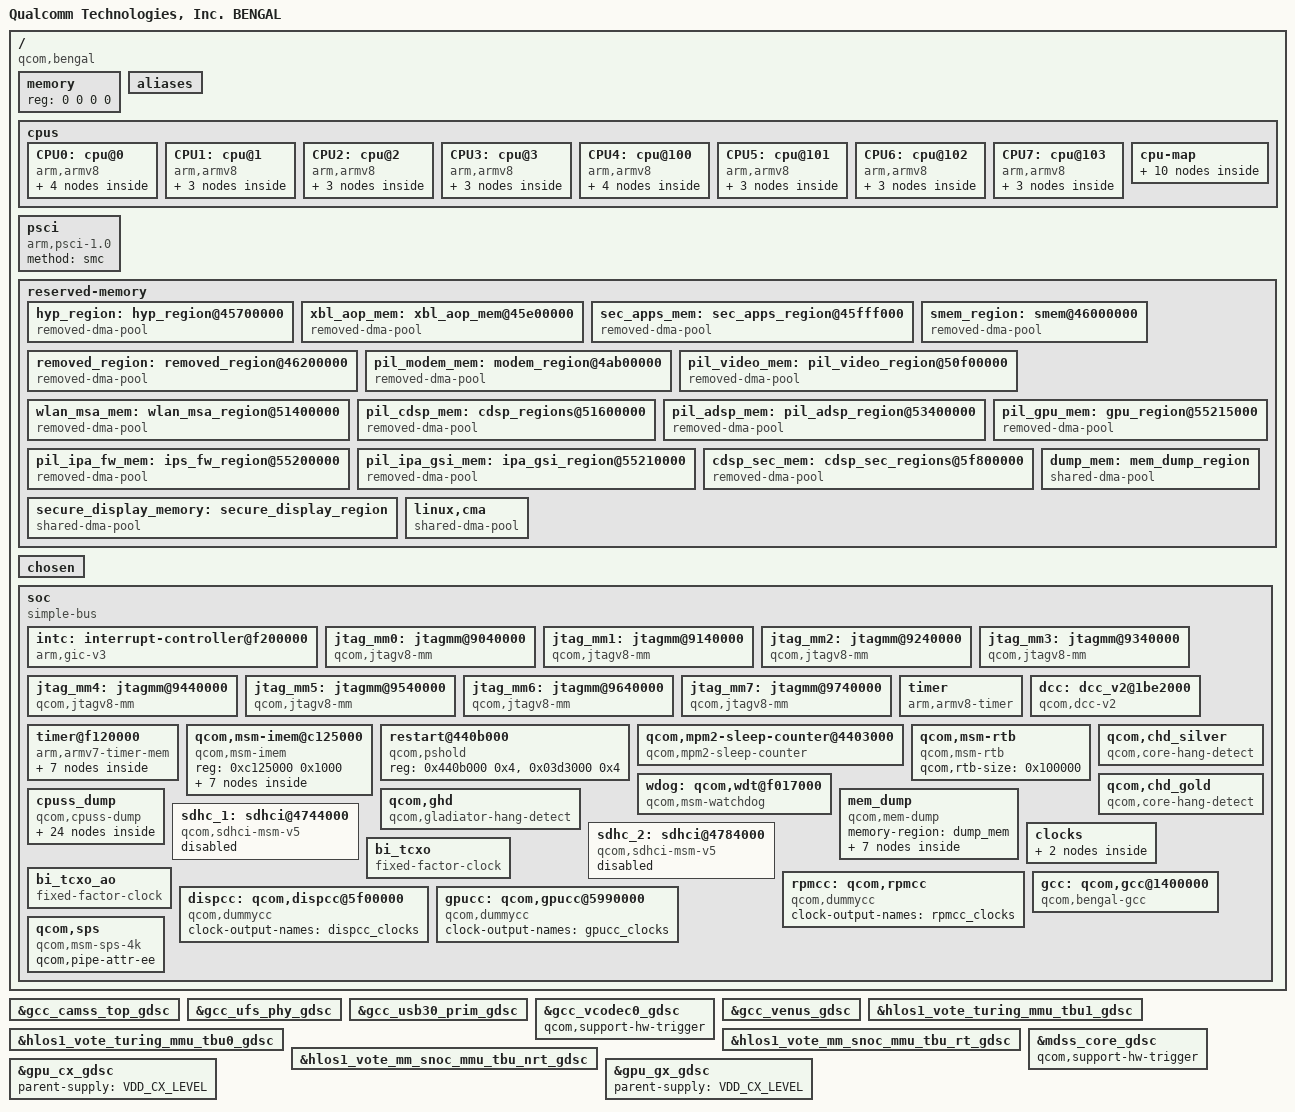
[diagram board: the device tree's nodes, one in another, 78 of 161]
#include <dt-bindings/interrupt-controller/arm-gic.h>
#include <dt-bindings/clock/qcom,rpmcc.h>
#include <dt-bindings/clock/qcom,dispcc-bengal.h>
#include <dt-bindings/clock/qcom,gcc-bengal.h>
#include <dt-bindings/clock/qcom,gpucc-bengal.h>

/ {
	model = "Qualcomm Technologies, Inc. BENGAL";
	compatible = "qcom,bengal";
	qcom,msm-id = <417 0x10000>;
	interrupt-parent = <&intc>;

	#address-cells = <2>;
	#size-cells = <2>;
	memory { device_type = "memory"; reg = <0 0 0 0>; };

	aliases {
		sdhc1 = &sdhc_1; /* SDC1 eMMC slot */
		sdhc2 = &sdhc_2; /* SDC2 SD Card slot */
	};

	cpus {
		#address-cells = <2>;
		#size-cells = <0>;

		CPU0: cpu@0 {
			device_type = "cpu";
			compatible = "arm,armv8";
			reg = <0x0 0x0>;
			capacity-dmips-mhz = <1024>;
			dynamic-power-coefficient = <100>;
			enable-method = "psci";
			d-cache-size = <0x8000>;
			i-cache-size = <0x8000>;
			next-level-cache = <&L2_0>;
			L2_0: l2-cache {
				compatible = "arm,arch-cache";
				cache-level = <2>;
			};

			L1_I_0: l1-icache {
				compatible = "arm,arch-cache";
				qcom,dump-size = <0x9040>;
			};

			L1_D_0: l1-dcache {
				compatible = "arm,arch-cache";
				qcom,dump-size = <0x9040>;
			};

			L1_TLB_0: l1-tlb {
				qcom,dump-size = <0x2800>;
			};
		};

		CPU1: cpu@1 {
			device_type = "cpu";
			compatible = "arm,armv8";
			reg = <0x0 0x1>;
			capacity-dmips-mhz = <1024>;
			dynamic-power-coefficient = <100>;
			enable-method = "psci";
			d-cache-size = <0x8000>;
			i-cache-size = <0x8000>;
			next-level-cache = <&L2_0>;

			L1_I_1: l1-icache {
				compatible = "arm,arch-cache";
				qcom,dump-size = <0x9040>;
			};

			L1_D_1: l1-dcache {
				compatible = "arm,arch-cache";
				qcom,dump-size = <0x9040>;
			};

			L1_TLB_1: l1-tlb {
				qcom,dump-size = <0x2800>;
			};
		};

		CPU2: cpu@2 {
			device_type = "cpu";
			compatible = "arm,armv8";
			reg = <0x0 0x2>;
			capacity-dmips-mhz = <1024>;
			dynamic-power-coefficient = <100>;
			enable-method = "psci";
			d-cache-size = <0x8000>;
			i-cache-size = <0x8000>;
			next-level-cache = <&L2_0>;

			L1_I_2: l1-icache {
				compatible = "arm,arch-cache";
				qcom,dump-size = <0x9040>;
			};

			L1_D_2: l1-dcache {
				compatible = "arm,arch-cache";
				qcom,dump-size = <0x9040>;
			};

			L1_TLB_2: l1-tlb {
				qcom,dump-size = <0x2800>;
			};
		};

		CPU3: cpu@3 {
			device_type = "cpu";
			compatible = "arm,armv8";
			reg = <0x0 0x3>;
			capacity-dmips-mhz = <1024>;
			dynamic-power-coefficient = <100>;
			enable-method = "psci";
			d-cache-size = <0x8000>;
			i-cache-size = <0x8000>;
			next-level-cache = <&L2_0>;

			L1_I_3: l1-icache {
				compatible = "arm,arch-cache";
				qcom,dump-size = <0x9040>;
			};

			L1_D_3: l1-dcache {
				compatible = "arm,arch-cache";
				qcom,dump-size = <0x9040>;
			};

			L1_TLB_3: l1-tlb {
				qcom,dump-size = <0x2800>;
			};
		};

		CPU4: cpu@100 {
			device_type = "cpu";
			compatible = "arm,armv8";
			reg = <0x0 0x100>;
			enable-method = "psci";
			capacity-dmips-mhz = <1638>;
			dynamic-power-coefficient = <282>;
			d-cache-size = <0x10000>;
			i-cache-size = <0x10000>;
			next-level-cache = <&L2_1>;
			L2_1: l2-cache {
				compatible = "arm,arch-cache";
				cache-level = <2>;
			};

			L1_I_100: l1-icache {
				compatible = "arm,arch-cache";
				qcom,dump-size = <0x12000>;
			};

			L1_D_100: l1-dcache {
				compatible = "arm,arch-cache";
				qcom,dump-size = <0x12000>;
			};

			L1_TLB_100: l1-tlb {
				qcom,dump-size = <0x4800>;
			};
		};

		CPU5: cpu@101 {
			device_type = "cpu";
			compatible = "arm,armv8";
			reg = <0x0 0x101>;
			capacity-dmips-mhz = <1638>;
			dynamic-power-coefficient = <282>;
			enable-method = "psci";
			d-cache-size = <0x10000>;
			i-cache-size = <0x10000>;
			next-level-cache = <&L2_1>;

			L1_I_101: l1-icache {
				compatible = "arm,arch-cache";
				qcom,dump-size = <0x12000>;
			};

			L1_D_101: l1-dcache {
				compatible = "arm,arch-cache";
				qcom,dump-size = <0x12000>;
			};

			L1_TLB_101: l1-tlb {
				qcom,dump-size = <0x4800>;
			};
		};

		CPU6: cpu@102 {
			device_type = "cpu";
			compatible = "arm,armv8";
			reg = <0x0 0x102>;
			capacity-dmips-mhz = <1638>;
			dynamic-power-coefficient = <282>;
			enable-method = "psci";
			d-cache-size = <0x10000>;
			i-cache-size = <0x10000>;
			next-level-cache = <&L2_1>;

			L1_I_102: l1-icache {
				compatible = "arm,arch-cache";
				qcom,dump-size = <0x12000>;
			};

			L1_D_102: l1-dcache {
				compatible = "arm,arch-cache";
				qcom,dump-size = <0x12000>;
			};

			L1_TLB_102: l1-tlb {
				qcom,dump-size = <0x4800>;
			};
		};

		CPU7: cpu@103 {
			device_type = "cpu";
			compatible = "arm,armv8";
			reg = <0x0 0x103>;
			capacity-dmips-mhz = <1638>;
			dynamic-power-coefficient = <282>;
			enable-method = "psci";
			d-cache-size = <0x10000>;
			i-cache-size = <0x10000>;
			next-level-cache = <&L2_1>;

			L1_I_103: l1-icache {
				compatible = "arm,arch-cache";
				qcom,dump-size = <0x12000>;
			};

			L1_D_103: l1-dcache {
				compatible = "arm,arch-cache";
				qcom,dump-size = <0x12000>;
			};

			L1_TLB_103: l1-tlb {
				qcom,dump-size = <0x4800>;
			};
		};

		cpu-map {
			cluster0 {
				core0 {
					cpu = <&CPU0>;
				};

				core1 {
					cpu = <&CPU1>;
				};

				core2 {
					cpu = <&CPU2>;
				};

				core3 {
					cpu = <&CPU3>;
				};
			};

			cluster1 {
				core0 {
					cpu = <&CPU4>;
				};

				core1 {
					cpu = <&CPU5>;
				};

				core2 {
					cpu = <&CPU6>;
				};

				core3 {
					cpu = <&CPU7>;
				};
			};
		};
	};

	psci {
		compatible = "arm,psci-1.0";
		method = "smc";
	};

	reserved-memory {
		#address-cells = <2>;
		#size-cells = <2>;
		ranges;

		hyp_region: hyp_region@45700000 {
			compatible = "removed-dma-pool";
			no-map;
			reg = <0x0 0x45700000 0x0 0x600000>;
		};

		xbl_aop_mem: xbl_aop_mem@45e00000 {
			compatible = "removed-dma-pool";
			no-map;
			reg = <0x0 0x45e00000 0x0 0x140000>;
		};

		sec_apps_mem: sec_apps_region@45fff000 {
			compatible = "removed-dma-pool";
			no-map;
			reg = <0x0 0x45fff000 0x0 0x1000>;
		};

		smem_region: smem@46000000 {
			compatible = "removed-dma-pool";
			no-map;
			reg = <0x0 0x46000000 0x0 0x200000>;
		};

		removed_region: removed_region@46200000 {
			compatible = "removed-dma-pool";
			no-map;
			reg = <0x0 0x46200000 0x0 0x3900000>;
		};

		pil_modem_mem: modem_region@4ab00000 {
			compatible = "removed-dma-pool";
			no-map;
			reg = <0x0 0x4ab00000 0x0 0x6400000>;
		};

		pil_video_mem: pil_video_region@50f00000 {
			compatible = "removed-dma-pool";
			no-map;
			reg = <0x0 0x50f00000 0x0 0x500000>;
		};

		wlan_msa_mem: wlan_msa_region@51400000 {
			compatible = "removed-dma-pool";
			no-map;
			reg = <0x0 0x51400000 0x0 0x200000>;
		};

		pil_cdsp_mem: cdsp_regions@51600000 {
			compatible = "removed-dma-pool";
			no-map;
			reg = <0x0 0x51600000 0x0 0x1e00000>;
		};

		pil_adsp_mem: pil_adsp_region@53400000 {
			compatible = "removed-dma-pool";
			no-map;
			reg = <0x0 0x53400000 0x0 0x1e00000>;
		};

		pil_ipa_fw_mem: ips_fw_region@55200000 {
			compatible = "removed-dma-pool";
			no-map;
			reg = <0x0 0x55200000 0x0 0x10000>;
		};

		pil_ipa_gsi_mem: ipa_gsi_region@55210000 {
			compatible = "removed-dma-pool";
			no-map;
			reg = <0x0 0x55210000 0x0 0x5000>;
		};

		pil_gpu_mem: gpu_region@55215000 {
			compatible = "removed-dma-pool";
			no-map;
			reg = <0x0 0x55215000 0x0 0x2000>;
		};

		cdsp_sec_mem: cdsp_sec_regions@5f800000 {
			compatible = "removed-dma-pool";
			no-map;
			reg = <0x0 0x5f800000 0x0 0x1e00000>;
		};

		secure_display_memory: secure_display_region {
			compatible = "shared-dma-pool";
			alloc-ranges = <0 0x00000000 0 0xffffffff>;
			reusable;
			alignment = <0 0x400000>;
			size = <0 0x5c00000>;
		};

		dump_mem: mem_dump_region {
			compatible = "shared-dma-pool";
			reusable;
			size = <0 0x400000>;
		};

		/* global autoconfigured region for contiguous allocations */
		linux,cma {
			compatible = "shared-dma-pool";
			alloc-ranges = <0x0 0x00000000 0x0 0xffffffff>;
			reusable;
			alignment = <0x0 0x400000>;
			size = <0x0 0x2000000>;
			linux,cma-default;
		};
	};

	chosen {
		bootargs = "rcupdate.rcu_expedited=1 rcu_nocbs=0-7";
	};

	soc: soc { };
};

&soc {
	#address-cells = <1>;
	#size-cells = <1>;
	ranges = <0 0 0 0xffffffff>;
	compatible = "simple-bus";

	intc: interrupt-controller@f200000 {
		compatible = "arm,gic-v3";
		#interrupt-cells = <3>;
		interrupt-controller;
		#redistributor-regions = <1>;
		redistributor-stride = <0x0 0x20000>;
		reg = <0xf200000 0x10000>,     /* GICD */
		      <0xf300000 0x100000>;    /* GICR * 8 */
		interrupts = <1 9 4>;
	};

	jtag_mm0: jtagmm@9040000 {
		compatible = "qcom,jtagv8-mm";
		reg = <0x9040000 0x1000>;
		reg-names = "etm-base";

		clocks = <&rpmcc RPM_SMD_QDSS_CLK>;
		clock-names = "core_clk";

		qcom,coresight-jtagmm-cpu = <&CPU0>;
	};

	jtag_mm1: jtagmm@9140000 {
		compatible = "qcom,jtagv8-mm";
		reg = <0x9140000 0x1000>;
		reg-names = "etm-base";

		clocks = <&rpmcc RPM_SMD_QDSS_CLK>;
		clock-names = "core_clk";

		qcom,coresight-jtagmm-cpu = <&CPU1>;
	};

	jtag_mm2: jtagmm@9240000 {
		compatible = "qcom,jtagv8-mm";
		reg = <0x9240000 0x1000>;
		reg-names = "etm-base";

		clocks = <&rpmcc RPM_SMD_QDSS_CLK>;
		clock-names = "core_clk";

		qcom,coresight-jtagmm-cpu = <&CPU2>;
	};

	jtag_mm3: jtagmm@9340000 {
		compatible = "qcom,jtagv8-mm";
		reg = <0x9340000 0x1000>;
		reg-names = "etm-base";

		clocks = <&rpmcc RPM_SMD_QDSS_CLK>;
		clock-names = "core_clk";

		qcom,coresight-jtagmm-cpu = <&CPU3>;
	};

	jtag_mm4: jtagmm@9440000 {
		compatible = "qcom,jtagv8-mm";
		reg = <0x9440000 0x1000>;
		reg-names = "etm-base";

		clocks = <&rpmcc RPM_SMD_QDSS_CLK>;
		clock-names = "core_clk";

		qcom,coresight-jtagmm-cpu = <&CPU4>;
	};

	jtag_mm5: jtagmm@9540000 {
		compatible = "qcom,jtagv8-mm";
		reg = <0x9540000 0x1000>;
		reg-names = "etm-base";

		clocks = <&rpmcc RPM_SMD_QDSS_CLK>;
		clock-names = "core_clk";

		qcom,coresight-jtagmm-cpu = <&CPU5>;
	};

	jtag_mm6: jtagmm@9640000 {
		compatible = "qcom,jtagv8-mm";
		reg = <0x9640000 0x1000>;
		reg-names = "etm-base";

		clocks = <&rpmcc RPM_SMD_QDSS_CLK>;
		clock-names = "core_clk";

		qcom,coresight-jtagmm-cpu = <&CPU6>;
	};

	jtag_mm7: jtagmm@9740000 {
		compatible = "qcom,jtagv8-mm";
		reg = <0x9740000 0x1000>;
		reg-names = "etm-base";

		clocks = <&rpmcc RPM_SMD_QDSS_CLK>;
		clock-names = "core_clk";

		qcom,coresight-jtagmm-cpu = <&CPU7>;
	};

	timer {
		compatible = "arm,armv8-timer";
		interrupts = <1 1 0xf08>,
			     <1 2 0xf08>,
			     <1 3 0xf08>,
			     <1 0 0xf08>;
		clock-frequency = <19200000>;
	};

	dcc: dcc_v2@1be2000 {
		compatible = "qcom,dcc-v2";
		reg = <0x1be2000 0x1000>,
			<0x1bee000 0x2000>;
		reg-names = "dcc-base", "dcc-ram-base";
		dcc-ram-offset = <0x2000>;
	};

	timer@f120000 {
		#address-cells = <1>;
		#size-cells = <1>;
		ranges;
		compatible = "arm,armv7-timer-mem";
		reg = <0xf120000 0x1000>;
		clock-frequency = <19200000>;

		frame@f121000 {
			frame-number = <0>;
			interrupts = <0 8 0x4>,
				     <0 7 0x4>;
			reg = <0xf121000 0x1000>,
			      <0xf122000 0x1000>;
		};

		frame@f123000 {
			frame-number = <1>;
			interrupts = <0 9 0x4>;
			reg = <0xf123000 0x1000>;
			status = "disabled";
		};

		frame@f124000 {
			frame-number = <2>;
			interrupts = <0 10 0x4>;
			reg = <0xf124000 0x1000>;
			status = "disabled";
		};

		frame@f125000 {
			frame-number = <3>;
			interrupts = <0 11 0x4>;
			reg = <0xf125000 0x1000>;
			status = "disabled";
		};

		frame@f126000 {
			frame-number = <4>;
			interrupts = <0 12 0x4>;
			reg = <0xf126000 0x1000>;
			status = "disabled";
		};

		frame@f127000 {
			frame-number = <5>;
			interrupts = <0 13 0x4>;
			reg = <0xf127000 0x1000>;
			status = "disabled";
		};

		frame@f128000 {
			frame-number = <6>;
			interrupts = <0 14 0x4>;
			reg = <0xf128000 0x1000>;
			status = "disabled";
		};
	};

	qcom,msm-imem@c125000 {
		compatible = "qcom,msm-imem";
		reg = <0xc125000 0x1000>;
		ranges = <0x0 0xc125000 0x1000>;
		#address-cells = <1>;
		#size-cells = <1>;

		mem_dump_table@10 {
			compatible = "qcom,msm-imem-mem_dump_table";
			reg = <0x10 0x8>;
		};

		restart_reason@65c {
			compatible = "qcom,msm-imem-restart_reason";
			reg = <0x65c 0x4>;
		};

		dload_type@1c {
			compatible = "qcom,msm-imem-dload-type";
			reg = <0x1c 0x4>;
		};

		boot_stats@6b0 {
			compatible = "qcom,msm-imem-boot_stats";
			reg = <0x6b0 0x20>;
		};

		kaslr_offset@6d0 {
			compatible = "qcom,msm-imem-kaslr_offset";
			reg = <0x6d0 0xc>;
		};

		pil@94c {
			compatible = "qcom,msm-imem-pil";
			reg = <0x94c 0xc8>;
		};

		diag_dload@c8 {
			compatible = "qcom,msm-imem-diag-dload";
			reg = <0xc8 0xc8>;
		};
	};

	restart@440b000 {
		compatible = "qcom,pshold";
		reg = <0x440b000 0x4>,
		      <0x03d3000 0x4>;
		reg-names = "pshold-base", "tcsr-boot-misc-detect";
	};

	qcom,mpm2-sleep-counter@4403000 {
		compatible = "qcom,mpm2-sleep-counter";
		reg = <0x4403000 0x1000>;
		clock-frequency = <32768>;
	};

	qcom,msm-rtb {
		compatible = "qcom,msm-rtb";
		qcom,rtb-size = <0x100000>;
	};

	wdog: qcom,wdt@f017000 {
		compatible = "qcom,msm-watchdog";
		reg = <0xf017000 0x1000>;
		reg-names = "wdt-base";
		interrupts = <0 3 0>, <0 4 0>;
		qcom,bark-time = <11000>;
		qcom,pet-time = <9360>;
		qcom,ipi-ping;
		qcom,wakeup-enable;
		qcom,scandump-sizes = <0x40000>;
	};

	qcom,chd_silver {
		compatible = "qcom,core-hang-detect";
		label = "silver";
		qcom,threshold-arr = <0x0f1880b0 0x0f1980b0
				      0x0f1a80b0 0x0f1b80b0>;
		qcom,config-arr = <0x0f1880b8 0x0f1980b8
				   0x0f1a80b8 0x0f1b80b8>;
	};

	qcom,chd_gold {
		compatible = "qcom,core-hang-detect";
		label = "gold";
		qcom,threshold-arr = <0x0f0880b0 0x0f0980b0
				      0x0f0a80b0 0x0f0b80b0>;
		qcom,config-arr = <0x0f0880b8 0x0f0980b8
				   0x0f0a80b8 0x0f0b80b8>;
	};

	qcom,ghd {
		compatible = "qcom,gladiator-hang-detect";
		qcom,threshold-arr = <0x0f1d141c 0x0f1d1420
				      0x0f1d1424 0x0f1d1428
				      0x0f1d142c 0x0f1d1430>;
		qcom,config-reg = <0x0f1d1434>;
	};

	cpuss_dump: cpuss_dump {
		compatible = "qcom,cpuss-dump";
		qcom,l1_i_cache0 {
			qcom,dump-node = <&L1_I_0>;
			qcom,dump-id = <0x60>;
		};

		qcom,l1_i_cache1 {
			qcom,dump-node = <&L1_I_1>;
			qcom,dump-id = <0x61>;
		};

		qcom,l1_i_cache2 {
			qcom,dump-node = <&L1_I_2>;
			qcom,dump-id = <0x62>;
		};

		qcom,l1_i_cache3 {
			qcom,dump-node = <&L1_I_3>;
			qcom,dump-id = <0x63>;
		};

		qcom,l1_i_cache100 {
			qcom,dump-node = <&L1_I_100>;
			qcom,dump-id = <0x64>;
		};

		qcom,l1_i_cache101 {
			qcom,dump-node = <&L1_I_101>;
			qcom,dump-id = <0x65>;
		};

		qcom,l1_i_cache102 {
			qcom,dump-node = <&L1_I_102>;
			qcom,dump-id = <0x66>;
		};

		qcom,l1_i_cache103 {
			qcom,dump-node = <&L1_I_103>;
			qcom,dump-id = <0x67>;
		};

		qcom,l1_d_cache0 {
			qcom,dump-node = <&L1_D_0>;
			qcom,dump-id = <0x80>;
		};

		qcom,l1_d_cache1 {
			qcom,dump-node = <&L1_D_1>;
			qcom,dump-id = <0x81>;
		};

		qcom,l1_d_cache2 {
			qcom,dump-node = <&L1_D_2>;
			qcom,dump-id = <0x82>;
		};

		qcom,l1_d_cache3 {
			qcom,dump-node = <&L1_D_3>;
			qcom,dump-id = <0x83>;
		};

		qcom,l1_d_cache100 {
			qcom,dump-node = <&L1_D_100>;
			qcom,dump-id = <0x84>;
		};

		qcom,l1_d_cache101 {
			qcom,dump-node = <&L1_D_101>;
			qcom,dump-id = <0x85>;
		};

		qcom,l1_d_cache102 {
			qcom,dump-node = <&L1_D_102>;
			qcom,dump-id = <0x86>;
		};

		qcom,l1_d_cache103 {
			qcom,dump-node = <&L1_D_103>;
			qcom,dump-id = <0x87>;
		};

		qcom,l1_tlb_dump0 {
			qcom,dump-node = <&L1_TLB_0>;
			qcom,dump-id = <0x20>;
		};

		qcom,l1_tlb_dump1 {
			qcom,dump-node = <&L1_TLB_1>;
			qcom,dump-id = <0x21>;
		};

		qcom,l1_tlb_dump2 {
			qcom,dump-node = <&L1_TLB_2>;
			qcom,dump-id = <0x22>;
		};

		qcom,l1_tlb_dump3 {
			qcom,dump-node = <&L1_TLB_3>;
			qcom,dump-id = <0x23>;
		};

		qcom,l1_tlb_dump100 {
			qcom,dump-node = <&L1_TLB_100>;
			qcom,dump-id = <0x24>;
		};

		qcom,l1_tlb_dump101 {
			qcom,dump-node = <&L1_TLB_101>;
			qcom,dump-id = <0x25>;
		};

		qcom,l1_tlb_dump102 {
			qcom,dump-node = <&L1_TLB_102>;
			qcom,dump-id = <0x26>;
		};

		qcom,l1_tlb_dump103 {
			qcom,dump-node = <&L1_TLB_103>;
			qcom,dump-id = <0x27>;
		};
	};

	mem_dump {
		compatible = "qcom,mem-dump";
		memory-region = <&dump_mem>;

		rpm_sw {
			qcom,dump-size = <0x28000>;
			qcom,dump-id = <0xea>;
		};

		pmic {
			qcom,dump-size = <0x10000>;
			qcom,dump-id = <0xe4>;
		};

		fcm {
			qcom,dump-size = <0x8400>;
			qcom,dump-id = <0xee>;
		};

		tmc_etf {
			qcom,dump-size = <0x8000>;
			qcom,dump-id = <0xf0>;
		};

		etr_reg {
			qcom,dump-size = <0x1000>;
			qcom,dump-id = <0x100>;
		};

		etf_reg {
			qcom,dump-size = <0x1000>;
			qcom,dump-id = <0x101>;
		};

		misc_data {
			qcom,dump-size = <0x1000>;
			qcom,dump-id = <0xe8>;
		};
	};

	sdhc_1: sdhci@4744000 {
		compatible = "qcom,sdhci-msm-v5", "qcom,sdhci-msm-cqe";
		reg = <0x4744000 0x1000>, <0x4745000 0x1000>;
		reg-names = "hc_mem", "cqhci_mem";

		interrupts = <GIC_SPI 348 IRQ_TYPE_LEVEL_HIGH>,
				<GIC_SPI 352 IRQ_TYPE_LEVEL_HIGH>;
		interrupt-names = "hc_irq", "pwr_irq";

		qcom,bus-width = <8>;
		qcom,large-address-bus;

		qcom,clk-rates = <400000 20000000 25000000 50000000 100000000
						192000000 384000000>;
		qcom,bus-speed-mode = "HS400_1p8v", "HS200_1p8v", "DDR_1p8v";

		qcom,devfreq,freq-table = <50000000 200000000>;

		qcom,scaling-lower-bus-speed-mode = "DDR52";

		clocks = <&gcc GCC_SDCC1_AHB_CLK>,
			<&gcc GCC_SDCC1_APPS_CLK>,
			<&gcc GCC_SDCC1_ICE_CORE_CLK>;
		clock-names = "iface_clk", "core_clk", "ice_core_clk";

		qcom,ice-clk-rates = <300000000 100000000>;

		/* DLL HSR settings. Refer go/hsr - <Target> DLL settings */
		qcom,dll-hsr-list = <0x000f642c 0x0 0x0 0x00010800 0x80040873>;

		qcom,nonremovable;
		status = "disabled";
	};

	sdhc_2: sdhci@4784000 {
		compatible = "qcom,sdhci-msm-v5";
		reg = <0x4784000 0x1000>;
		reg-names = "hc_mem";

		interrupts = <GIC_SPI 350 IRQ_TYPE_LEVEL_HIGH>,
				<GIC_SPI 353 IRQ_TYPE_LEVEL_HIGH>;
		interrupt-names = "hc_irq", "pwr_irq";

		qcom,bus-width = <4>;
		qcom,large-address-bus;

		qcom,clk-rates = <400000 20000000 25000000
				50000000 100000000 202000000>;
		qcom,bus-speed-mode = "SDR12", "SDR25", "SDR50", "DDR50",
				      "SDR104";

		qcom,devfreq,freq-table = <50000000 202000000>;

		clocks = <&gcc GCC_SDCC2_AHB_CLK>,
			<&gcc GCC_SDCC2_APPS_CLK>;
		clock-names = "iface_clk", "core_clk";

		/* DLL HSR settings. Refer go/hsr - <Target> DLL settings */
		qcom,dll-hsr-list = <0x0007642c 0x0 0x0 0x00010800 0x80040873>;

		status = "disabled";
	};

	clocks {
		xo_board: xo_board {
			compatible = "fixed-clock";
			clock-frequency = <19200000>;
			clock-output-names = "xo_board";
			#clock-cells = <0>;
		};

		sleep_clk: sleep_clk {
			compatible = "fixed-clock";
			clock-frequency = <32764>;
			clock-output-names = "sleep_clk";
			#clock-cells = <0>;
		};
	};

	bi_tcxo: bi_tcxo {
		compatible = "fixed-factor-clock";
		clocks = <&xo_board>;
		clock-mult = <1>;
		clock-div = <1>;
		#clock-cells = <0>;
	};

	bi_tcxo_ao: bi_tcxo_ao {
		compatible = "fixed-factor-clock";
		clocks = <&xo_board>;
		clock-mult = <1>;
		clock-div = <1>;
		#clock-cells = <0>;
	};

	rpmcc: qcom,rpmcc {
		compatible = "qcom,dummycc";
		clock-output-names = "rpmcc_clocks";
		#clock-cells = <1>;
		#reset-cells = <1>;
	};

	gcc: qcom,gcc@1400000 {
		compatible = "qcom,bengal-gcc", "syscon";
		reg = <0x1400000 0x1f0000>;
		reg-names = "cc_base";
		vdd_cx-supply = <&VDD_CX_LEVEL>;
		vdd_cx_ao-supply = <&VDD_CX_LEVEL_AO>;
		vdd_mx-supply = <&VDD_MX_LEVEL>;
		#clock-cells = <1>;
		#reset-cells = <1>;
	};

	dispcc: qcom,dispcc@5f00000 {
		compatible = "qcom,dummycc";
		clock-output-names = "dispcc_clocks";
		#clock-cells = <1>;
		#reset-cells = <1>;
	};

	gpucc: qcom,gpucc@5990000 {
		compatible = "qcom,dummycc";
		clock-output-names = "gpucc_clocks";
		#clock-cells = <1>;
		#reset-cells = <1>;
	};

	qcom,sps {
		compatible = "qcom,msm-sps-4k";
		qcom,pipe-attr-ee;
	};
};

#include "bengal-gdsc.dtsi"
#include "bengal-usb.dtsi"
#include "bengal-ion.dtsi"

&gcc_camss_top_gdsc {
	status = "ok";
};

&gcc_ufs_phy_gdsc {
	status = "ok";
};

&gcc_usb30_prim_gdsc {
	status = "ok";
};

&gcc_vcodec0_gdsc {
	qcom,support-hw-trigger;
	status = "ok";
};

&gcc_venus_gdsc {
	status = "ok";
};

&hlos1_vote_turing_mmu_tbu1_gdsc {
	status = "ok";
};

&hlos1_vote_turing_mmu_tbu0_gdsc {
	status = "ok";
};

&hlos1_vote_mm_snoc_mmu_tbu_rt_gdsc {
	status = "ok";
};

&hlos1_vote_mm_snoc_mmu_tbu_nrt_gdsc {
	status = "ok";
};

&mdss_core_gdsc {
	qcom,support-hw-trigger;
	status = "ok";
};

&gpu_cx_gdsc {
	parent-supply = <&VDD_CX_LEVEL>;
	status = "ok";
};

&gpu_gx_gdsc {
	parent-supply = <&VDD_CX_LEVEL>;
	status = "ok";
};

#include "msm-arm-smmu-bengal.dtsi"
#include "bengal-regulator.dtsi"
#include "bengal-pinctrl.dtsi"
